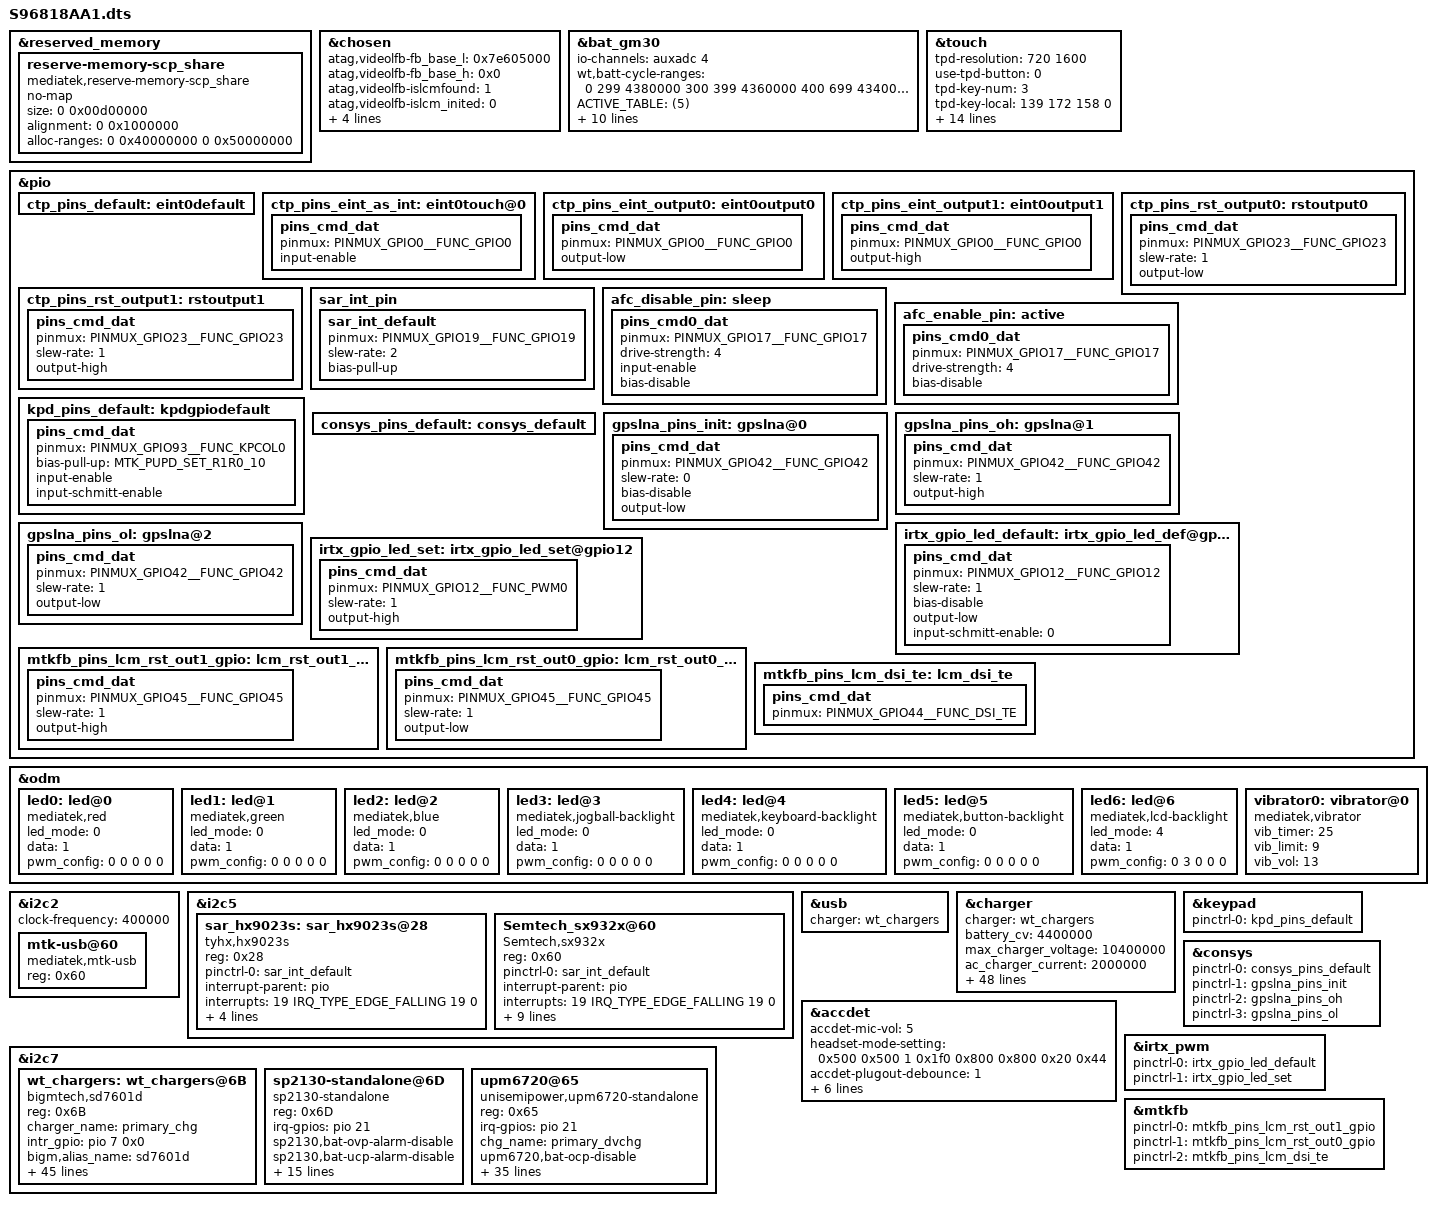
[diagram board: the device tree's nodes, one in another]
// SPDX-License-Identifier: GPL-2.0
/*
 * Copyright (c) 2019 MediaTek Inc.
 */

#include <dt-bindings/interrupt-controller/irq.h>
#include <dt-bindings/interrupt-controller/arm-gic.h>
#include <dt-bindings/pinctrl/mt6768-pinfunc.h>

&reserved_memory {
	reserve-memory-scp_share {
		compatible = "mediatek,reserve-memory-scp_share";
		no-map;
		size = <0 0x00d00000>;
		alignment = <0 0x1000000>;
		alloc-ranges = <0 0x40000000 0 0x50000000>;
	};
};

/* chosen */
&chosen {

	atag,videolfb-fb_base_l = <0x7e605000>;
	atag,videolfb-fb_base_h = <0x0>;
	atag,videolfb-islcmfound = <1>;
	atag,videolfb-islcm_inited = <0>;
	atag,videolfb-fps= <6000>;
	atag,videolfb-vramSize= <0x017e8000>;
	atag,videolfb-lcmname=
		"hx83112b_fhdp_dsi_cmd_auo_rt5081_drv";
};

&bat_gm30 {
	io-channels = <&auxadc 4>;
	io-channel-names = "batteryID-channel";
#include "mediatek/bat_setting/battery_N28_BYD_4V4_5000mAh.dtsi"
#include "mediatek/bat_setting/battery_N28_ATL_4V4_5000mAh.dtsi"
#include "mediatek/bat_setting/battery_N28_GF_4V4_5000mAh.dtsi"

/* +S96818AA1-2906, churui1.wt, ADD, 20230621, batt_full_capacity_New */
	wt,batt-cycle-ranges = <
		0   299  4380000
		300 399  4360000
		400 699  4340000
		700 999  4320000
		1000 999999 4270000>;
	ACTIVE_TABLE = <(5)>;
	g_FG_PSEUDO100_cv4380 = <
		96 96 96 100
		96 96 96 100
		96 96 96 100
		96 96 96 100
		96 96 96 100
		100 100 100 100
		100 100 100 100
		100 100 100 100
		100 100 100 100
		100 100 100 100>;
	g_FG_PSEUDO100_cv4360 = <
		94 94 94 100
		94 94 94 100
		94 94 94 100
		94 94 94 100
		94 94 94 100
		100 100 100 100
		100 100 100 100
		100 100 100 100
		100 100 100 100
		100 100 100 100>;
	g_FG_PSEUDO100_cv4340 = <
		91  92  91 100
		91  92  91 100
		91  92  91 100
		91  91  91 100
		91  91  91 100
		100 100 100 100
		100 100 100 100
		100 100 100 100
		100 100 100 100
		100 100 100 100>;
	g_FG_PSEUDO100_cv4320 = <
		88  89  89 100
		88  89  89 100
		88  89  88 100
		88  89  88 100
		88  88  88 100
		100 100 100 100
		100 100 100 100
		100 100 100 100
		100 100 100 100
		100 100 100 100>;
	g_FG_PSEUDO100_cv4270 = <
		86  86  86 100
		86  86  86 100
		86  86  86 100
		85  85  85 100
		85  85  85 100
		100 100 100 100
		100 100 100 100
		100 100 100 100
		100 100 100 100
		100 100 100 100>;
/* -S96818AA1-2906, churui1.wt, ADD, 20230621, batt_full_capacity_New */
};

/* TOUCH start */
&touch {
	tpd-resolution = <720 1600>;
	use-tpd-button = <0>;
	tpd-key-num = <3>;
	tpd-key-local= <139 172 158 0>;
	tpd-key-dim-local = <200 2000 100 40 515 2000 100 40 800 2000 100 40 0 0 0 0>;
	tpd-max-touch-num = <10>;
	tpd-filter-enable = <0>;
	tpd-filter-pixel-density = <192>;
	tpd-filter-custom-prameters = <0 0 0 0 0 0 0 0 0 0 0 0>;
	tpd-filter-custom-speed = <0 0 0>;
//+S96818AA1-1936,daijun1.wt,modify,2023/05/19,n28-tp prevent crashes caused by DTS
	pinctrl-names = "default", "state_eint_as_int", "state_eint_output0",
		"state_eint_output1", "state_rst_output0", "state_rst_output1";
	pinctrl-0 = <&ctp_pins_default>;
	pinctrl-1 = <&ctp_pins_eint_as_int>;
	pinctrl-2 = <&ctp_pins_eint_output0>;
	pinctrl-3 = <&ctp_pins_eint_output1>;
	pinctrl-4 = <&ctp_pins_rst_output0>;
	pinctrl-5 = <&ctp_pins_rst_output1>;
//-S96818AA1-1936,daijun1.wt,modify,2023/05/19,n28-tp prevent crashes caused by DTS
	status = "okay";
};

&pio {
//+S96818AA1-1936,daijun1.wt,modify,2023/05/19,n28-tp prevent crashes caused by DTS
	ctp_pins_default: eint0default {
	};
//+S96818AA1-1936,daijun1.wt,modify,2023/05/24,ft8057 Modify res control method
	ctp_pins_eint_as_int: eint0touch@0 {
		pins_cmd_dat {
			pinmux = <PINMUX_GPIO0__FUNC_GPIO0>;
			input-enable;
		};
	};
	ctp_pins_eint_output0: eint0output0 {
		pins_cmd_dat {
			pinmux = <PINMUX_GPIO0__FUNC_GPIO0>;
			output-low;
		};
	};
	ctp_pins_eint_output1: eint0output1 {
		pins_cmd_dat {
			pinmux = <PINMUX_GPIO0__FUNC_GPIO0>;
			output-high;
		};
	};
//-S96818AA1-1936,daijun1.wt,modify,2023/05/19,n28-tp prevent crashes caused by DTS
	ctp_pins_rst_output0: rstoutput0 {
		pins_cmd_dat {
			pinmux = <PINMUX_GPIO23__FUNC_GPIO23>;
			slew-rate = <1>;
			output-low;
		};
	};
	ctp_pins_rst_output1: rstoutput1 {
		pins_cmd_dat {
			pinmux = <PINMUX_GPIO23__FUNC_GPIO23>;
			slew-rate = <1>;
			output-high;
		};
	};
//-S96818AA1-1936,daijun1.wt,modify,2023/05/24,ft8057 Modify res control method
};
/* TOUCH end */

&odm {
	led0:led@0 {
		compatible = "mediatek,red";
		led_mode = <0>;
		data = <1>;
		pwm_config = <0 0 0 0 0>;
	};
	led1:led@1 {
		compatible = "mediatek,green";
		led_mode = <0>;
		data = <1>;
		pwm_config = <0 0 0 0 0>;
	};
	led2:led@2 {
		compatible = "mediatek,blue";
		led_mode = <0>;
		data = <1>;
		pwm_config = <0 0 0 0 0>;
	};
	led3:led@3 {
		compatible = "mediatek,jogball-backlight";
		led_mode = <0>;
		data = <1>;
		pwm_config = <0 0 0 0 0>;
	};
	led4:led@4 {
		compatible = "mediatek,keyboard-backlight";
		led_mode = <0>;
		data = <1>;
		pwm_config = <0 0 0 0 0>;
	};
	led5:led@5 {
		compatible = "mediatek,button-backlight";
		led_mode = <0>;
		data = <1>;
		pwm_config = <0 0 0 0 0>;
	};
	led6:led@6 {
		compatible = "mediatek,lcd-backlight";
		led_mode = <4>;
		data = <1>;
		pwm_config = <0 3 0 0 0>;
	};
	vibrator0:vibrator@0 {
		compatible = "mediatek,vibrator";
		vib_timer = <25>;
		vib_limit = <9>;
		vib_vol= <13>;
	};
};

&i2c2 {
	clock-frequency = <400000>;

	mtk-usb@60 {
		compatible = "mediatek,mtk-usb";
		reg = <0x60>;
		status = "okay";
	};
};

&i2c5 {
    status = "okay";
    sar_hx9023s:sar_hx9023s@28 {
        compatible = "tyhx,hx9023s";
        reg = <0x28>;
        pinctrl-names = "sar_int_default";
        pinctrl-0 = <&sar_int_default>;
        interrupt-parent = <&pio>;
        interrupts = <19 IRQ_TYPE_EDGE_FALLING 19 0>;
        tyhx,irq-gpio = <&pio 19 0x0>;
        tyhx,irq-flags = <2>;
        tyhx,channel-flag = <0x07>;
        tyhx5,channel-flag = <0x1F>;
        status = "okay";
    };

	Semtech_sx932x@60 {
        compatible = "Semtech,sx932x";
        reg = <0x60>;
        pinctrl-names = "sar_int_default";
        pinctrl-0 = <&sar_int_default>;
        interrupt-parent = <&pio>;
        interrupts = <19 IRQ_TYPE_EDGE_FALLING 19 0>;
        Semtech,nirq-gpio = <&pio 19 0x00>;
        Semtech,reg-num = <46>;
        Semtech5,main-phases = <0x07>;
        Semtech5,ref-phases = <0x18>;
        Semtech5,reg-num = <85>;
        Semtech5,reg-init = <
			0x4004 0x00000070
			0x4008 0x00000000
			0x4054 0x00000400
			0x42C0 0x08000000
			0x42C4 0x0000003F
			0x800C 0x00000000
			0x8010 0x00000000
			0x8014 0x00000000
			0x8018 0x00000000
			0x801C 0x00000031
			0x8020 0x001F0000
			0x8028 0x3FFE82DA
			0x802C 0x10000A76
			0x8030 0x3FF78261
			0x8034 0x10000A6E
			0x8038 0x3DFF8024
			0x803C 0x10000A76
			0x8040 0x3FBF8267
			0x8044 0x10000A96
			0x8048 0x2FFF82E1
			0x804C 0x0000088E
			0x8050 0x80001EE6
			0x8054 0x10323700
			0x8058 0x20630030
			0x805C 0x00005300
			0x8060 0x00000000
			0x8064 0x00000000
			0x8068 0x00000000
			0x806C 0x1F001F00
			0x8070 0x00010000
			0x8074 0x10323B05
			0x8078 0x20630030
			0x807C 0x00005300
			0x8080 0x00000000
			0x8084 0x00000000
			0x8088 0x00000000
			0x808C 0x00200020
			0x8090 0x10022805
			0x8094 0x10323705
			0x8098 0x20630030
			0x809C 0x00005300
			0x80A0 0x00000000
			0x80A4 0x00000000
			0x80A8 0x00000000
			0x80AC 0x00000000
			0x80B0 0x00000000
			0x80B4 0x1652FF05
			0x80B8 0x20630030
			0x80BC 0x00005300
			0x80C0 0x00000000
			0x80C4 0x00000000
			0x80C8 0x00000000
			0x80CC 0x00000000
			0x80D0 0x00000000
			0x80D4 0x1652FF05
			0x80D8 0x20630031
			0x80DC 0x7F805300
			0x80E0 0x00000000
			0x80E4 0x00000000
			0x80E8 0x00000000
			0x80EC 0x00000000
			0x80F0 0x00000000
			0x80F4 0x10162800
			0x80F8 0x20400031
			0x80FC 0x54AC5300
			0x8100 0x00000000
			0x8104 0x00000000
			0x8108 0x00000000
			0x810C 0x00000000
			0x8110 0x00000000
			0x8124 0x0400000B
			0x8128 0x0400000C
			0x812C 0x00000000
			0x8130 0x00000000
			0x8134 0x00000000
			0x8138 0x00000000
			0x813C 0x00000000
			0x8140 0x00000000
			0x8144 0x00000000
			0x8148 0x00000000
			0x814C 0x00000000
			0x81A4 0x01C40011
			0x4280 0x0000000F
			0x8024 0x10000A6E
			0x4280 0x0000000E
        >;
        Semtech,reg-init  = /bits/ 8 <
			0x10 0x16
			0x20 0x20
			0x23 0x00
			0x24 0x65
			0x26 0x00
			0x27 0x65
			0x28 0x01 /*PH0 to CS0 input*/
			0x29 0x10
			0x2A 0x04 /*PH2 CS2-input,CS1-dync,CS0-HZ*/
			0x2B 0x3D
			0x2C 0x12
			0x2D 0x08
			0x30 0x0B
			0x31 0x0B
			0x32 0x3D
			0x33 0x2D
			0x34 0x0C
			0x35 0x00
			0x36 0x1A
			0x37 0x12
			0x40 0x00
			0x41 0x00
			0x42 0x12
			0x43 0x04
			0x44 0x00
			0x45 0x05
			0x46 0x00
			0x47 0x00
			0x48 0x00
			0x49 0x00
			0x4A 0x00
			0x4B 0x00
			0x4C 0x00
			0x4D 0x00
			0x4E 0x80
			0x4F 0x0C
			0x50 0x14
			0x51 0x70
			0x52 0x20
			0x53 0x00
			0x54 0x00
			0x05 0x70
			0x06 0x00
			0x07 0x80
			0x08 0x01
			0x11 0x20
        >;
        status = "ok";
    };
};

&pio {
    sar_int_pin {
        sar_int_default: sar_int_default {
            pinmux = <PINMUX_GPIO19__FUNC_GPIO19>;
            slew-rate = <2>;
            bias-pull-up;
        };
    };
};


&i2c7 {
    wt_chargers:wt_chargers@6B {
		compatible = "bigmtech,sd7601d","upm,upm6910d","southchip,sc89601s";
		reg = <0x6B>;
		charger_name = "primary_chg";
		intr_gpio = <&pio 7 0x0>;

		bigm,alias_name = "sd7601d";
		bigm,vlimit_mv = <4500>;
		bigm,ilimit_ma = <3000>;
		bigm,vsysmin_mv = <3400>;
		bigm,cc_ma = <3000>;
		bigm,cv_mv = <4400>;
		bigm,pre_ma = <540>;
		bigm,eoc_ma = <240>;
		bigm,rechg_mv = <100>;
		bigm,target_hv = <0>;

		upm,eint_name = "upm6910";
		upm,upm6910,charge-detect-enable;
		upm,upm6910,usb-vlim = <4500>;
		upm,upm6910,usb-ilim = <2000>;
		upm,upm6910,usb-vreg = <4200>;
		upm,upm6910,usb-ichg = <2000>;
		upm,upm6910,stat-pin-ctrl = <0>;
		upm,upm6910,precharge-current = <180>;
		upm,upm6910,termination-current = <240>; //set eoc current 240mA
		upm,upm6910,boost-voltage = <5150>; //set otg voltage 5.15V
		upm,upm6910,boost-current = <1200>;
		upm,upm6910,vac-ovp-threshold = <14000>;

		sc,sc8960x,charge-detect-enable;
		sc,sc8960x,enable_term;
		sc8960x,pfm-dis = <0>; /*0: enable, 1: disable*/
		sc8960x,vsys-min = <5>; /*0: 2.6V, 1: 2.8V, 2: 3.0V,
                    3: 3.2V, 4: 3.4V, 5: 3.5V, 6:3.6V, 7: 3.7V*/
		sc8960x,vbat-low-otg = <0>; /*0: 2.8V, 1: 2.5V*/
		sc8960x,ipre-chg = <2>; /*60 + val * 60, unit:mA*/
		sc8960x,itermination = <2>; /*60 + val * 60, unit:mA*/
		sc8960x,vbat-volt = <44>; /*3848 + val * 8, unit:mV*/
		sc8960x,top-off-timer = <0>; /*0: dis, 1: 15min, 2: 20min 3: 45min*/
		sc8960x,vrechg-volt = <0>; /*0: 100mV, 1: 200mV*/
		sc8960x,en-termination = <1>; /*0: disable, 1: enable*/
		sc8960x,wdt-timer = <0>; /*0: disable, 1: 40s, 2: 80s, 3：160s*/
		sc8960x,en-chg-saft-timer = <1>; /*0: disable, 1: enable*/
		sc8960x,charge-timer = <1>; /*0: 5hrs, 1: 10hrs*/
		sc8960x,vac-ovp = <3>; /*0: 5.8V, 1: 6.4V, 2: 11V, 3: 14.2V*/
		sc8960x,iboost = <1>; /*0: 0.5A, 1: 1.2A*/
		sc8960x,vboost = <12>; /*3900 + val * 100, unit:mV*/
		sc8960x,vindpm-track = <0>; /*0: disable, 1:200mV, 2:250mV, 3:300mV*/
		sc8960x,vindpm-int-mask = <1>; /*0: not mask, 1: mask*/
		sc8960x,iindpm-int-mask = <1>; /*0: not mask, 1: mask*/
		sc8960x,vpre-to-cc = <0>; /*0: 3V, 1: 2.8V*/
		sc8960x,auto-dpdm-en = <1>; /*0: disale, 1: enable*/
		sc8960x,ntc-pin-dis = <1>; /*0: enable, 1: disable*/

		charger = <&wt_chargers>;
		status = "okay";
	};

	sp2130-standalone@6D {
		compatible = "sp2130-standalone";
		reg = <0x6D>;
		irq-gpios = <&pio 21 0>;

		sp2130,bat-ovp-alarm-disable;
		sp2130,bat-ucp-alarm-disable;
		sp2130,bat-ucp-disable;
		sp2130,bat-therm-disable;
		sp2130,bus-therm-disable;
		sp2130,die-therm-disable;

		sp2130,bat-ovp-threshold = <4525>;
		sp2130,bat-ovp-alarm-threshold = <4490>;
		sp2130,bat-ocp-threshold = <7000>;
		sp2130,bat-ocp-alarm-threshold = <6000>;
		sp2130,bus-ovp-threshold = <11000>;
		sp2130,bus-ovp-alarm-threshold = <11000>;

		sp2130,bat-therm-threshold = <0x15>;
		sp2130,bus-therm-threshold = <0x15>;
		sp2130,die-therm-threshold = <145>;

		sp2130,ac-ovp-threshold = <11000>;
		sp2130,sense-resistor-mohm = <2>;
	};

    upm6720@65{
		status = "ok";
		compatible = "unisemipower,upm6720-standalone";
		reg = <0x65>;
		irq-gpios = <&pio 21 0>;
        chg_name = "primary_dvchg";

		// upm6720,bat-ovp-disable;
		upm6720,bat-ocp-disable;
		upm6720,bat-ocp-alm-disable;
		// upm6720,bus-ucp-disable;
		// upm6720,bus-rcp-disable;
		// upm6720,vout-ovp-disable;
		// upm6720,tdie-flt-disable;
/*+S96818AA1-1936,zhouxiaopeng2.wt,MODIFY,20230517,disable The temperature detection function*/
		upm6720,tsbus-flt-disable;
		upm6720,tsbat-flt-disable;
/*-S96818AA1-1936,zhouxiaopeng2.wt,MODIFY,20230517,disable The temperature detection function*/
		upm6720,wdt-disable;
		upm6720,vbus-errhi-disable;

		upm6720,bat-ovp-threshold = <4525>;			/* unit: 1mV */
		upm6720,bat-ocp-threshold = <8200>;			/* unit: 1mA */
		upm6720,bus-ovp-threshold = <10500>;		/* unit: 1mV set as 10.5V */
		upm6720,bus-ocp-threshold = <3500>;			/* unit: 1mA */
		upm6720,bus-ucp-threshold = <250>;			/* unit: 1mA */
		upm6720,bus-rcp-threshold = <300>;			/* unit: 1mA */
		upm6720,vac1-ovp-threshold = <10500>;		/* unit: 1mV programmed threshold set as 10.5V */
		upm6720,vac2-ovp-threshold = <10500>;		/* unit: 1mV programmed threshold set as 10.5V */
		upm6720,vout-ovp-threshold = <5000>;		/* unit: 1mV */
		upm6720,tdie-flt-threshold = <140>;			/* unit: 1℃ */
		upm6720,tsbus-flt-threshold = <4102>;		/* unit: 0.001% */
		upm6720,tsbat-flt-threshold = <4102>;		/* unit: 0.001% */

		// upm6720,bat-ovp-mask;
		// upm6720,bat-ocp-mask;
		// upm6720,bus-ovp-mask;
		// upm6720,bus-ocp-mask;
		// upm6720,bus-ucp-mask;
		// upm6720,bus-rcp-mask;
		// upm6720,vout-ovp-mask;
		// upm6720,vac1-ovp-mask;
		// upm6720,vac2-ovp-mask;

		// upm6720,vout-present-mask;
		// upm6720,vac1-present-mask;
		// upm6720,vac2-present-mask;
		// upm6720,vbus-present-mask;
		// upm6720,acrb1-config-mask;
		// upm6720,acrb2-config-mask;
		// upm6720,cfly-short-mask;
		// upm6720,adc-done-mask;
		// upm6720,ss-timeout-mask;
		// upm6720,tsbus-flt-mask;
		// upm6720,tsbat-flt-mask;
		// upm6720,tdie-flt-mask;
		// upm6720,wd-mask;
		// upm6720,regn-good-mask;
		// upm6720,conv-active-mask;
		// upm6720,vbus-errhi-mask;

		// upm6720,bat-ovp-alm-disable;
		// upm6720,bat-ocp-alm-disable;
		// upm6720,bat-ucp-alm-disable;
		// upm6720,bus-ovp-alm-disable;
		// upm6720,tdie-alm-disable;

		upm6720,bat-ovp-alm-threshold = <4510>;		/* unit: 1mV */
		upm6720,bat-ocp-alm-threshold = <8000>;		/* unit: 1mA */
		upm6720,bat-ucp-alm-threshold = <0>;		/* unit: 1mA */
		upm6720,bus-ovp-alm-threshold = <11800>;	/* unit: 1mV */
		upm6720,bus-ocp-alm-threshold = <5000>;		/* unit: 1mA */
		upm6720,tdie-alm-threshold = <125>;			/* unit: 1℃ */

		// upm6720,bat-ovp-alm-mask;
		// upm6720,bat-ocp-alm-mask;
		// upm6720,bat-ucp-alm-mask;
		// upm6720,bus-ovp-alm-mask;
		// upm6720,bus-ocp-alm-mask;
		// upm6720,tsbus-tsbat-alm-mask;
		// upm6720,tdie-alm-mask;

		// upm6720,bus-pulldown-en;
		// upm6720,vac1-pulldown-en;
		// upm6720,vac2-pulldown-en;

		upm6720,sense-resistor-mohm = <5>;	/* unit: 1mohm */
		upm6720,ss-timeout = <10000>;		/* unit: 1ms */
		upm6720,wdt-set = <30000>;			/* unit: 1ms */
		upm6720,chg-config-1 = <1>;
		upm6720,fsw-set = <500>;
		upm6720,freq-shift = <0>;
		upm6720,ibus-ucp-fall-dg-sel = <0>;

		upm6720,adc-enable;
		upm6720,adc-rate = <0>;
		upm6720,adc-avg = <0>;
		upm6720,adc-avg-init = <0>;
		upm6720,adc-sample-bit = <0>;
		// upm6720,ibus-adc-disable;
		// upm6720,vbus-adc-disable;
		// upm6720,vac1-adc-disable;
		// upm6720,vac2-adc-disable;
		// upm6720,vout-adc-disable;
		// upm6720,vbat-adc-disable;
		// upm6720,ibat-adc-disable;
		// upm6720,tsbus-adc-disable;
		// upm6720,tsbat-adc-disable;
		// upm6720,tdie-adc-disable;
	};
};

/*
&mt6358_gauge {
	charger = <&wt_chargers>;
};
*/

&usb {
	charger = <&wt_chargers>;
};

&charger {
	charger = <&wt_chargers>;

	battery_cv = <4400000>;
	max_charger_voltage = <10400000>; /* software OVP protection set as 10.4V */
	ac_charger_current = <2000000>;
	ac_charger_input_current = <2000000>;
	pd_vbus_upper_bound = <9000000>;

	/* sw jeita */
	enable_sw_jeita;
	jeita_temp_above_t4_cv = <4100000>;
	jeita_temp_t3_to_t4_cv = <4100000>;
	jeita_temp_t2_to_t3_cv = <4400000>;
	jeita_temp_t1_to_t2_cv = <4400000>;
	jeita_temp_t0_to_t1_cv = <4400000>;
	jeita_temp_below_t0_cv = <4400000>;
	jeita_temp_above_t4_cc = <0>;
	jeita_temp_t3_to_t4_cc = <1400000>;
	jeita_temp_t2_to_t3_cc = <2000000>;
	jeita_temp_t1_to_t2_cc = <1200000>;
	jeita_temp_t0_to_t1_cc = <400000>;
	jeita_temp_below_t0_cc = <0>;
	temp_t4_thres = <55>;
	temp_t4_thres_minus_x_degree = <54>;
	temp_t3_thres = <45>;
	temp_t3_thres_minus_x_degree = <44>;
	temp_t2_thres = <10>;
	temp_t2_thres_plus_x_degree = <11>;
	temp_t1_thres = <5>;
	temp_t1_thres_plus_x_degree = <6>;
	temp_t0_thres = <1>;
	temp_t0_thres_plus_x_degree = <1>;
	temp_neg_10_thres = <0>;

	/* battery temperature protection */
	enable_min_charge_temp;
	min_charge_temp = <0>;
	min_charge_temp_plus_x_degree = <0>;
	max_charge_temp = <60>;
	max_charge_temp_minus_x_degree = <60>;

	enable_afc;  /*enable for afc fast charge */
	afc_switch_gpio_num = <91>;
	afc_switch_gpio = <&pio 91 0x0>;
	afc_data_gpio_num = <17>;
	afc_data_gpio = <&pio 17 0x0>;
	afc_start_battery_soc = <0>;
	afc_stop_battery_soc = <85>;
	afc_pre_input_curret = <500000>;
	afc_charger_input_current = <1670000>;
	afc_charger_current = <3000000>;
	afc_ichg_level_threshold = <1000000>;
	afc_min_charger_voltage = <4200000>;
	afc_max_charger_voltage = <9000000>;
	pinctrl-names = "active", "sleep";
	pinctrl-0 = <&afc_enable_pin>;
	pinctrl-1 = <&afc_disable_pin>;
/*+S96818AA1-9230 lijiawei,wt.modify upm6910 safetytimer function logic*/
	enable_sw_safety_timer;
	max_charging_time = <43200>;/* 12 hours */
/*-S96818AA1-9230 lijiawei,wt.modify upm6910 safetytimer function logic*/
};

&pio {
	afc_disable_pin: sleep {
		pins_cmd0_dat {
			pinmux = <PINMUX_GPIO17__FUNC_GPIO17>;
			drive-strength = <4>;
			input-enable;
			bias-disable;
		};
	};

	afc_enable_pin: active {
		pins_cmd0_dat {
			pinmux = <PINMUX_GPIO17__FUNC_GPIO17>;
			drive-strength = <4>;
			bias-disable;
		};
	};
};

/* accdet start */
/* +Req S96818AA1-1936 shenwenlei.wt 20230508 Modify micbias1 2.5v */
&accdet {
	/* accdet micbias voltage: 0x07,2.7v;0x05,2.5v;0x02,1.9v */
	accdet-mic-vol = <5>;
	headset-mode-setting = <0x500 0x500 1 0x1f0 0x800 0x800 0x20 0x44>;
	accdet-plugout-debounce = <1>;
	/*1:ACC mode, 2:low cost without in bias, 6:low cost with in bias*/
	accdet-mic-mode = <1>;
	/* eint_level_trigger: 8,LEVEL_LOW(DEF) ;4,LV_HIGH;others,LV_LOW */
	headset-eint-level-pol = <8>;
	/*min_3pole--max_3pole--min_4pole--max_4pole--vol_bias*/
	headset-vol-threshold = <0 590 591 2000 2500>;
	/*0--MD_MAX--UP_MAX--DW_MAX*/
	headset-three-key-threshold = <0 80 220 400>;
	headset-three-key-threshold-CDD = <0 121 192 600>;
	/*0--MD_MAX--VOICE_MAX--UP_MAX--DW_MAX*/
	headset-four-key-threshold = <0 58 121 192 400>;
	status = "okay";
};
/* -Req S96818AA1-1936 shenwenlei.wt 20230508 Modify micbias1 2.5v */
/* accdet end */

/* keypad start */
&keypad {
	pinctrl-names = "default";
	pinctrl-0 = <&kpd_pins_default>;
};

&pio {
	kpd_pins_default: kpdgpiodefault {
		pins_cmd_dat {
			pinmux = <PINMUX_GPIO93__FUNC_KPCOL0>;
			bias-pull-up = <MTK_PUPD_SET_R1R0_10>;
			input-enable;
			input-schmitt-enable;
		};
	};
};
/* keypad end */

/* CONSYS GPIO standardization */
&pio {
	consys_pins_default: consys_default {
	};
	gpslna_pins_init: gpslna@0 {
		pins_cmd_dat {
			pinmux = <PINMUX_GPIO42__FUNC_GPIO42>;
			slew-rate = <0>;
			bias-disable;
			output-low;
		};
	};
	gpslna_pins_oh: gpslna@1 {
		pins_cmd_dat {
			pinmux = <PINMUX_GPIO42__FUNC_GPIO42>;
			slew-rate = <1>;
			output-high;
		};
	};
	gpslna_pins_ol: gpslna@2 {
		pins_cmd_dat {
			pinmux = <PINMUX_GPIO42__FUNC_GPIO42>;
			slew-rate = <1>;
			output-low;
		};
	};
};
&consys {
	pinctrl-names = "default", "gps_lna_state_init",
		"gps_lna_state_oh", "gps_lna_state_ol";
	pinctrl-0 = <&consys_pins_default>;
	pinctrl-1 = <&gpslna_pins_init>;
	pinctrl-2 = <&gpslna_pins_oh>;
	pinctrl-3 = <&gpslna_pins_ol>;
	status = "okay";
};
/* CONSYS end */

/* IRTX GPIO Start */
&irtx_pwm {
	pinctrl-names = "irtx_gpio_led_default", "irtx_gpio_led_set";
	pinctrl-0 = <&irtx_gpio_led_default>;
	pinctrl-1 = <&irtx_gpio_led_set>;
	status = "okay";
};
&pio {
	/* IRTX GPIO Settings -Start */
	/* default: GPIO0, output, high */
	irtx_gpio_led_default:irtx_gpio_led_def@gpio12 {
		pins_cmd_dat {
			pinmux = <PINMUX_GPIO12__FUNC_GPIO12>;
			slew-rate = <1>;
			bias-disable;
			output-low;
			input-schmitt-enable = <0>;
		};
	};

	irtx_gpio_led_set:irtx_gpio_led_set@gpio12 {
		pins_cmd_dat {
			pinmux = <PINMUX_GPIO12__FUNC_PWM0>;
			slew-rate = <1>;
			output-high;
		};
	};
}; /* IRTX GPIO Settings -End */

/* DISPSYS GPIO standardization */
&pio {
	mtkfb_pins_lcm_rst_out1_gpio: lcm_rst_out1_gpio {
		pins_cmd_dat {
			pinmux = <PINMUX_GPIO45__FUNC_GPIO45>;
			slew-rate = <1>;
			output-high;
		};
	};

	mtkfb_pins_lcm_rst_out0_gpio: lcm_rst_out0_gpio {
		pins_cmd_dat {
			pinmux = <PINMUX_GPIO45__FUNC_GPIO45>;
			slew-rate = <1>;
			output-low;
		};
	};

	mtkfb_pins_lcm_dsi_te: lcm_dsi_te {
		pins_cmd_dat {
			pinmux = <PINMUX_GPIO44__FUNC_DSI_TE>;
		};
	};
};

&mtkfb {
	pinctrl-names =
		"lcm_rst_out1_gpio", "lcm_rst_out0_gpio",
		"mode_te_te";
	pinctrl-0 = <&mtkfb_pins_lcm_rst_out1_gpio>;
	pinctrl-1 = <&mtkfb_pins_lcm_rst_out0_gpio>;
	pinctrl-2 = <&mtkfb_pins_lcm_dsi_te>;
	status = "okay";
};

/* DISPSYS GPIO standardization end*/

#include "mediatek/S96818AA1/cust.dtsi"
#include "mediatek/cust_mt6768_lcm_module.dtsi"
#include "mediatek/cust_mt6768_camera_s96818.dtsi"
#include "mediatek/cust_mt6768_touch_720x1600.dtsi"
#include "mediatek/sia8001.dtsi"
/*End of this file, DO NOT ADD ANYTHING HERE*/
